# CY8C5888LTI_LP097 register map
File version: 0.1
CY8C58LP
Registers are 8-bit, read-write, no defined reset value unless marked. A register's access mark holds for its fields unless they carry their own. Offsets are from the block's base; lines under a group give offsets from that group; [hi:lo] are bit positions; {n}, {i} and the like mark numbered series; 'fields as' and 'values as' point back to an identical list; <NAME> marks a mode.

## Memory map
0x00000000 ADC
0x00000000 Debug_UART — UART
0x00000000 UART_Telit — UART
0x00000000 Telit_ControlReg
0x00000000 SleepTimer
0x00000000 RTC
0x00000000 Level_Sensor_UART — UART

## Debug_UART — UART
Base 0x00000000
0x40006445 TX_Debug_UART_TX_DATA — TX Data Register
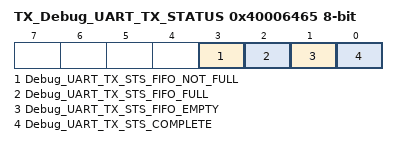
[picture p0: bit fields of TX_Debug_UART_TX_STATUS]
0x40006465 TX_Debug_UART_TX_STATUS — TX status register
  [3] Debug_UART_TX_STS_FIFO_NOT_FULL ro, [2] Debug_UART_TX_STS_FIFO_FULL ro, [1] Debug_UART_TX_STS_FIFO_EMPTY ro, [0] Debug_UART_TX_STS_COMPLETE ro

## UART_Telit — UART
Base 0x00000000
0x40006444 TX_UART_Telit_TX_DATA — TX Data Register
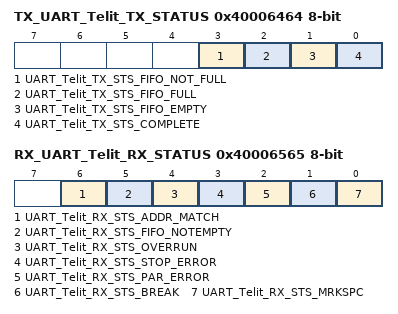
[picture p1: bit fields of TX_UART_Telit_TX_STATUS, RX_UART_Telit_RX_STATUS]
0x40006464 TX_UART_Telit_TX_STATUS — TX status register
  [3] UART_Telit_TX_STS_FIFO_NOT_FULL ro, [2] UART_Telit_TX_STS_FIFO_FULL ro, [1] UART_Telit_TX_STS_FIFO_EMPTY ro, [0] UART_Telit_TX_STS_COMPLETE ro
0x40006525 RX_UART_Telit_RX_ADDRESS1 — RX Address1 Register
0x40006535 RX_UART_Telit_RX_ADDRESS2 — RX Address2 Register
0x40006545 RX_UART_Telit_RX_DATA — RX Data Register
0x40006565 RX_UART_Telit_RX_STATUS — RX status register
  [6] UART_Telit_RX_STS_ADDR_MATCH ro, [5] UART_Telit_RX_STS_FIFO_NOTEMPTY ro, [4] UART_Telit_RX_STS_OVERRUN ro, [3] UART_Telit_RX_STS_STOP_ERROR ro, [2] UART_Telit_RX_STS_PAR_ERROR ro, [1] UART_Telit_RX_STS_BREAK ro, [0] UART_Telit_RX_STS_MRKSPC ro

## Telit_ControlReg
Base 0x00000000
0x40006477 Telit_ControlReg_CONTROL_REG

## SleepTimer
Base 0x00000000
0x40004381 SleepTimer_CTW_INTERVAL_REG — Timewheel Configuration Register 1
  [3:0] ctw_interval — Sets the central timewheel interval.
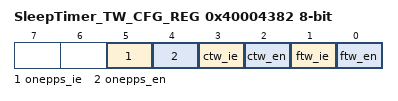
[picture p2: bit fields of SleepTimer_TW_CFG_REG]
0x40004382 SleepTimer_TW_CFG_REG — Timewheel Configuration Register 2
  [5] onepps_ie — When set and one pulse-per-second is enabled, an interrupt is issued when the pulse occurs.
    1=Enabled (One PPS interrupt is enabled); 0=Disabled (One PPS interrupt is disabled)
  [4] onepps_en — When set, the system returns to the active global power mode once every second.
    1=Enabled (One PPS is enabled); 0=Disabled (One PPS is disabled)
  [3] ctw_ie — When set and the central timewheel is enabled, an interrupt is issued when the central timewheel reaches the selected interval.
    1=Enabled (CTW interrupt is enabled); 0=Disabled (CTW interrupt is disabled)
  [2] ctw_en — When set, the system returns to the active global power mode when the central timewheel reaches the selected interval.
    1=Enabled (CTW is enabled); 0=Disabled (CTW is disabled)
  [1] ftw_ie — When set and the fast timewheel is enabled, an interrupt is issued when it reaches the terminal count.
    1=Enabled (FTW interrupt is enabled); 0=Disabled (FTW interrupt is disabled)
  [0] ftw_en — When set, the system returns to the active global power mode when the fast timewheel reaches the selected interval.
    1=Enabled (FTW is enabled); 0=Disabled (FTW is disabled)

## RTC
Base 0x00000000
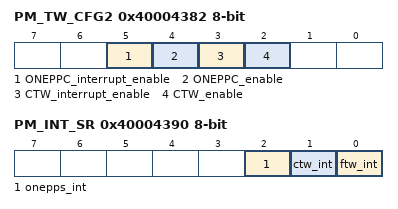
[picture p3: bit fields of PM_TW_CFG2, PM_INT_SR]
0x40004382 PM_TW_CFG2 — Power timers enable and interrupt enable configuration register
  [5] ONEPPC_interrupt_enable — When set and one pulse-per-second is enabled, an interrupt is issued when the pulse occurs
    1=Enabled (The ONEPPC interrupt is issued. Only if ONEPPC is enabled.); 0=Disabled (No ONEPPC interrupt is issued.)
  [4] ONEPPC_enable
    1=Enabled (The ONEPPC is enabled.); 0=Disabled (The ONEPPC is disabled.)
  [3] CTW_interrupt_enable — An interrupt issue when the CTW reaches the selected interval
    1=Enabled (The CTW interrupt is issued. Only if CTW is enabled.); 0=Disabled (No CTW interrupt is issued.)
  [2] CTW_enable
    1=Enabled (The CTW is enabled.); 0=Disabled (The CTW is disabled.)
0x40004390 PM_INT_SR — Power Manager Interrupt Status Register
  [2] onepps_int — When set, a onepps event has occured.
  [1] ctw_int — When set, a limited active ready event has occured
  [0] ftw_int — When set, a fast timewheel event has occured
